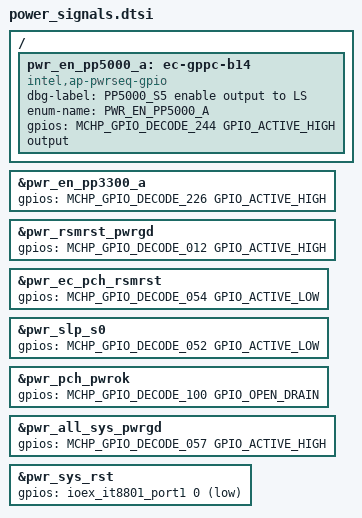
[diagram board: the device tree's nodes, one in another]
/* Copyright 2025 The ChromiumOS Authors
 * Use of this source code is governed by a BSD-style license that can be
 * found in the LICENSE file.
 */

#include "../power_signals.dtsi"

/* TODO: b:430093425 - Currently, previous Revision RVP where gpio is
 * used to generate 5V signal. Remove this gpio - pwr_en_pp5000_a after
 * moving to new RVP version.
 */
/ {
	pwr_en_pp5000_a: ec-gppc-b14 {
		compatible = "intel,ap-pwrseq-gpio";
		dbg-label = "PP5000_S5 enable output to LS";
		enum-name = "PWR_EN_PP5000_A";
		gpios = <MCHP_GPIO_DECODE_244 GPIO_ACTIVE_HIGH>;
		output;
	};
};
&pwr_en_pp3300_a {
	gpios = <MCHP_GPIO_DECODE_226 GPIO_ACTIVE_HIGH>;
};
&pwr_rsmrst_pwrgd {
	gpios = <MCHP_GPIO_DECODE_012 GPIO_ACTIVE_HIGH>;
};
&pwr_ec_pch_rsmrst {
	gpios = <MCHP_GPIO_DECODE_054 GPIO_ACTIVE_LOW>;
};
&pwr_slp_s0 {
	gpios = <MCHP_GPIO_DECODE_052 GPIO_ACTIVE_LOW>;
};
&pwr_pch_pwrok {
	gpios = <MCHP_GPIO_DECODE_100 GPIO_OPEN_DRAIN>;
};
&pwr_all_sys_pwrgd {
	gpios = <MCHP_GPIO_DECODE_057 GPIO_ACTIVE_HIGH>;
};
&pwr_sys_rst {
	gpios = <&ioex_it8801_port1 0 (GPIO_ACTIVE_LOW|GPIO_OPEN_DRAIN)>;
};
